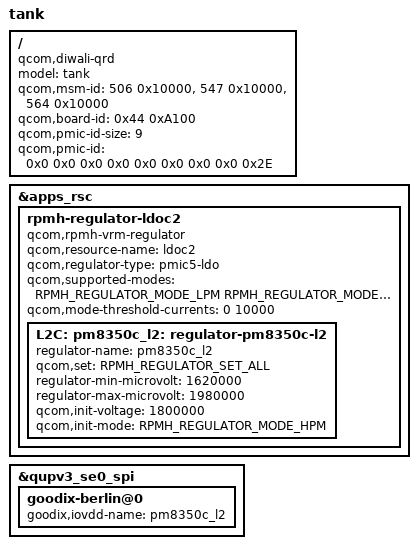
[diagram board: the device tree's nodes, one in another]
/* Copyright (c) 2022, The Linux Foundation. All rights reserved.
 *
 * This program is free software; you can redistribute it and/or modify
 * it under the terms of the GNU General Public License version 2 and
 * only version 2 as published by the Free Software Foundation.
 *
 * This program is distributed in the hope that it will be useful,
 * but WITHOUT ANY WARRANTY; without even the implied warranty of
 * MERCHANTABILITY or FITNESS FOR A PARTICULAR PURPOSE.  See the
 * GNU General Public License for more details.
 */

/dts-v1/;
/plugin/;

#include "diwali-tank-common-overlay.dtsi"
#include <dt-bindings/regulator/qcom,rpmh-regulator-levels.h>

/ {
	model = "tank";
	compatible = "qcom,diwali-qrd", "qcom,diwali", "qcom,qrd", "moto,tank";
	qcom,msm-id = <506 0x10000>, <547 0x10000>, <564 0x10000>;
	qcom,board-id = <0x44 0xA100>;
	qcom,pmic-id-size = <9>;
	qcom,pmic-id = <0x0 0x0 0x0 0x0 0x0 0x0 0x0 0x0 0x2E>;
};

&apps_rsc {
	rpmh-regulator-ldoc2 {
		compatible = "qcom,rpmh-vrm-regulator";
		qcom,resource-name = "ldoc2";
		qcom,regulator-type = "pmic5-ldo";
		qcom,supported-modes =
			<RPMH_REGULATOR_MODE_LPM
			 RPMH_REGULATOR_MODE_HPM>;
		qcom,mode-threshold-currents = <0 10000>;
		L2C: pm8350c_l2: regulator-pm8350c-l2 {
			regulator-name = "pm8350c_l2";
			qcom,set = <RPMH_REGULATOR_SET_ALL>;
			regulator-min-microvolt = <1620000>;
			regulator-max-microvolt = <1980000>;
			qcom,init-voltage = <1800000>;
			qcom,init-mode = <RPMH_REGULATOR_MODE_HPM>;
		};
	};
};

&qupv3_se0_spi {
	goodix-berlin@0 {
		goodix,iovdd-name = "pm8350c_l2";
	};
};
